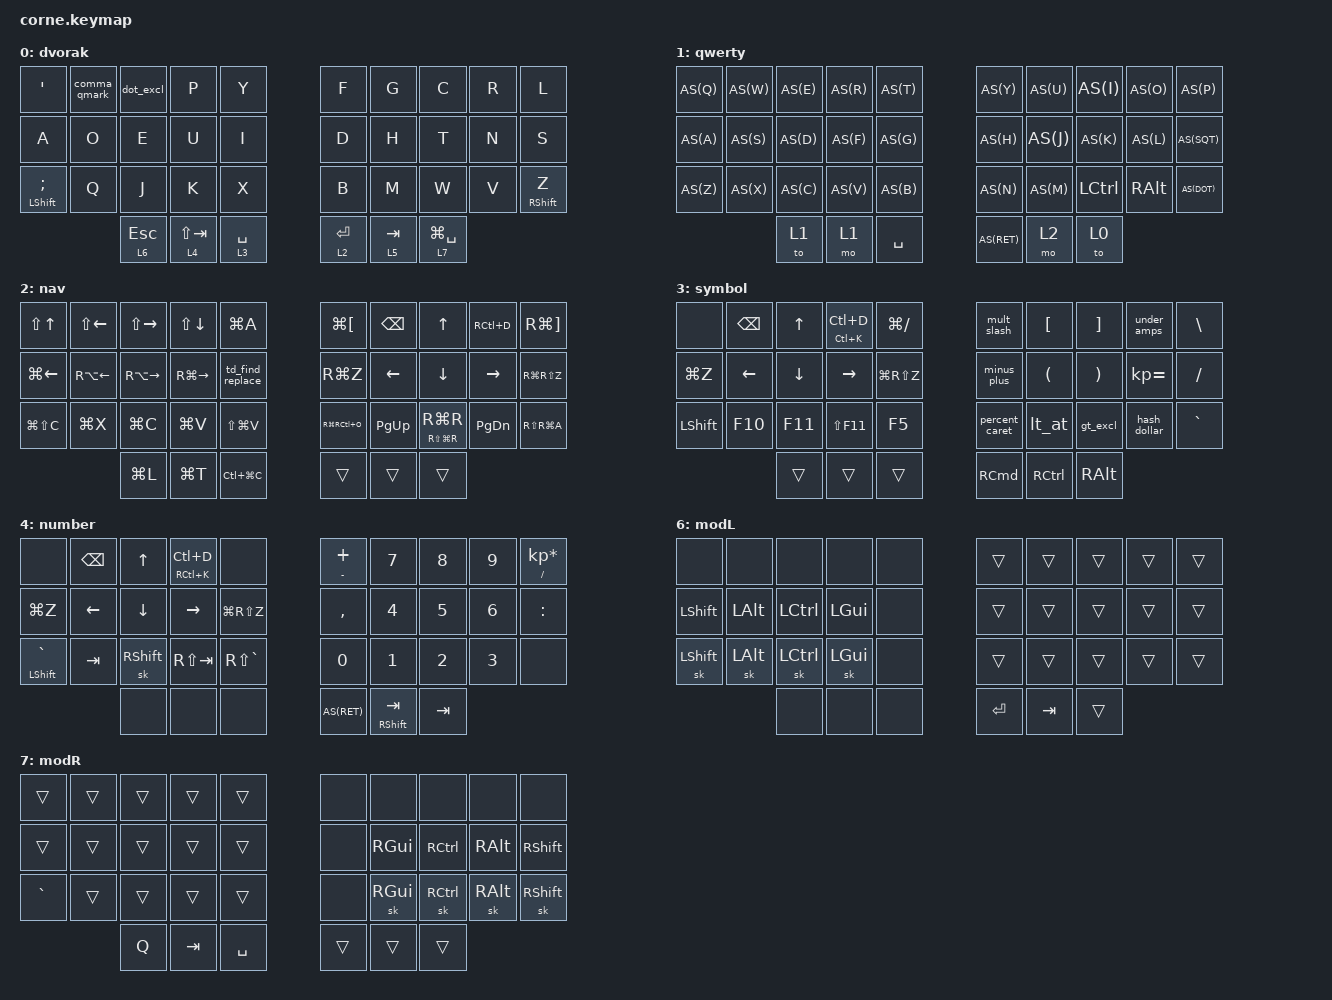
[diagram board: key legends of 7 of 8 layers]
/*
 * Copyright (c) 2020 The ZMK Contributors
 *
 * SPDX-License-Identifier: MIT
 */

#include <behaviors.dtsi>
#include <dt-bindings/zmk/keys.h>
#include <dt-bindings/zmk/bt.h>

#define AS(keycode) &as LS(keycode) keycode

/ {
    chosen {
        zmk,physical-layout = &foostan_corne_5col_layout;
    };

    behaviors {
        as: auto_shift {
            compatible = "zmk,behavior-hold-tap";
            #binding-cells = <2>;
            tapping_term_ms = <200>;
            quick_tap_ms = <0>;
            flavor = "tap-preferred";
            bindings = <&kp>, <&kp>;
        };
        lt_long: lt_long {
            compatible = "zmk,behavior-hold-tap";
            #binding-cells = <2>;
            tapping_term_ms = <350>;
            quick_tap_ms = <0>;
            flavor = "hold-preferred";
            bindings = <&mo>, <&kp>;
        };
        mt_shift: mt_shift {
            compatible = "zmk,behavior-hold-tap";
            #binding-cells = <2>;
            tapping_term_ms = <250>;
            quick_tap_ms = <0>;
            flavor = "hold-preferred";
            bindings = <&kp>, <&kp>;
        };
        td_find_replace: td_find_replace {
            compatible = "zmk,behavior-tap-dance";
            #binding-cells = <0>;
            tapping-term-ms = <200>;
            bindings = <&kp LG(F)>, <&kp LA(LG(F))>;
        };
        cmd_alt: cmd_alt {
            compatible = "zmk,behavior-mod-morph";
            label = "cmd alt";
            #binding-cells = <0>;
            bindings = <&sk LCMD>, <&sk LALT>;
            mods = <(MOD_LSFT|MOD_RSFT)>;
        };

        dot_excl: dot_excl {
            compatible = "zmk,behavior-mod-morph";
            label = "dot exc";
            #binding-cells = <0>;
            bindings = <&kp DOT >, <&kp EXCL >;
            mods = <(MOD_LSFT|MOD_RSFT)>;
        };
        comma_qmark: comma_qmark {
            compatible = "zmk,behavior-mod-morph";
            label = "comma question";
            #binding-cells = <0>;
            bindings = <&kp COMMA>, <&kp QMARK>;
            mods = <(MOD_LSFT|MOD_RSFT)>;
        };

        mult_slash: mult_slash {
            compatible = "zmk,behavior-mod-morph";
            label = "mult slash";
            #binding-cells = <0>;
            bindings = <&kp KP_MULTIPLY>, <&kp KP_SLASH>;
            mods = <(MOD_LSFT|MOD_RSFT)>;
        };
        minus_plus: minus_plus {
            compatible = "zmk,behavior-mod-morph";
            label = "minus plus";
            #binding-cells = <0>;
            bindings = <&kp KP_MINUS>, <&kp KP_PLUS>;
            mods = <(MOD_LSFT|MOD_RSFT)>;
        };

        zoom: zoom {
            compatible = "zmk,behavior-mod-morph";
            label = "minus plus";
            #binding-cells = <0>;
            bindings = <&kp RG(KP_PLUS)>, <&kp RG(KP_MINUS)>;
            mods = <(MOD_LSFT|MOD_RSFT)>;
        };

        percent_caret: percent_caret {
            compatible = "zmk,behavior-mod-morph";
            label = "caret percent";
            #binding-cells = <0>;
            bindings = <&kp PERCENT>, <&kp CARET>;
            mods = <(MOD_LSFT|MOD_RSFT)>;
        };
        lt_at: lt_at {
            compatible = "zmk,behavior-mod-morph";
            label = "lt at";
            #binding-cells = <0>;
            bindings = <&kp LT>, <&kp AT>;
            mods = <(MOD_LSFT|MOD_RSFT)>;
        };
        gt_excl: gt_excl {
            compatible = "zmk,behavior-mod-morph";
            label = "gt excl";
            #binding-cells = <0>;
            bindings = <&kp GT>, <&kp EXCL>;
            mods = <(MOD_LSFT|MOD_RSFT)>;
        };
        hash_dollar: hash_dollar {
            compatible = "zmk,behavior-mod-morph";
            label = "hash dollar";
            #binding-cells = <0>;
            bindings = <&kp HASH>, <&kp DOLLAR>;
            mods = <(MOD_LSFT|MOD_RSFT)>;
        };
        under_amps: under_amps {
            compatible = "zmk,behavior-mod-morph";
            label = "under amps";
            #binding-cells = <0>;
            bindings = <&kp UNDER>, <&kp AMPS>;
            mods = <(MOD_LSFT|MOD_RSFT)>;
        };
    };

    combos {
        compatible = "zmk,combos";
    };

    macros {
        tab_search: tab_search {
            compatible = "zmk,behavior-macro";
            #binding-cells = <0>;
            bindings
                = <&macro_tap &kp LG(L) &kp PERCENT &kp SPACE>
                ;
        };
        bookmark_search: bookmark_search {
            compatible = "zmk,behavior-macro";
            #binding-cells = <0>;
            bindings
                = <&macro_tap &kp LG(L) &kp STAR &kp SPACE>
                ;
        };


    };

        keymap {
            compatible = "zmk,keymap";

            dvorak: dvorak {
                display-name = "dvorak";
                bindings = <
   &kp SQT          &comma_qmark   &dot_excl    &kp P    &kp Y         &kp F    &kp G    &kp C    &kp R   &kp L
   &kp A            &kp O          &kp E        &kp U    &kp I         &kp D    &kp H    &kp T    &kp N   &kp S
   &mt_shift LSHIFT SEMI  &kp Q          &kp J        &kp  K    &kp X        &kp B    &kp M    &kp W    &kp V   &mt_shift RSHIFT Z
              &lt 6 ESC   &lt 4 LS(TAB)  &lt 3 SPACE        &lt 2 RET   &lt 5 TAB  &lt 7 LG(SPACE)
                        >;
                };

            qwerty: qwerty {
                        display-name = "qwerty";
                        bindings = <
   AS(Q) AS(W) AS(E) AS(R) AS(T)     AS(Y)   AS(U)  AS(I)     AS(O)     AS(P)
   AS(A) AS(S) AS(D) AS(F) AS(G)     AS(H)   AS(J)  AS(K)     AS(L)     AS(SQT)
   AS(Z) AS(X) AS(C) AS(V) AS(B)     AS(N)   AS(M)  &kp LCTRL  &kp RALT  AS(DOT)
        &to 1   &mo 1 &kp SPACE     AS(RET) &mo 2  &to 0
                        >;
                };

            nav: nav {
                        display-name = "nav";
                        bindings = <

   &kp LS(UP)           &kp LS(LEFT)     &kp LS(RIGHT)    &kp LS(DOWN)   &kp LG(A)               &kp LG(LBKT)     &kp BACKSPACE    &kp UP                 &kp RC(D)      &kp RG(RBKT)
   &kp LG(LEFT)         &kp RA(LEFT)     &kp RA(RIGHT)    &kp RG(RIGHT)  &td_find_replace         &kp RG(Z)        &kp LEFT         &kp DOWN               &kp RIGHT      &kp RG(RS(Z))
   &kp LG(LS(C))        &kp LG(X)        &kp LG(C)        &kp LG(V)      &kp LS(LG(V))           &kp RG(RC(O))      &kp PG_UP        &mt RS(LG(R)) RG(R)  &kp PG_DN      &kp RS(RG(A))
                                &kp LG(L)    &kp LG(T)    &kp LC(LG(C))                          &trans   &trans    &trans
                        >;
                };

            sym: sym {
                        display-name = "symbol";
                        bindings = <
&none          &kp BACKSPACE   &kp  UP         &mt LC(K) LC(D) &kp LG(SLASH)       &mult_slash      &kp LBKT    &kp RBKT    &under_amps    &kp BACKSLASH
&kp LG(Z)      &kp LEFT        &kp DOWN        &kp RIGHT       &kp LG(RS(Z))       &minus_plus      &kp LPAR    &kp RPAR    &kp KP_EQUAL   &kp SLASH
&kp LSHIFT     &kp F10         &kp F11         &kp LS(F11)     &kp F5              &percent_caret   &lt_at      &gt_excl    &hash_dollar   &kp GRAVE
                                            &trans   &trans    &trans              &kp RCMD     &kp RCTRL     &kp RALT
                        >;
                };

            num: num {
                        display-name = "number";
                        bindings = <
&none             &kp BACKSPACE   &kp  UP         &mt RC(K) LC(D) &none                   &mt MINUS PLUS  &kp N7       &kp N8       &kp N9       &mt SLASH KP_MULTIPLY
&kp LG(Z)         &kp LEFT        &kp DOWN        &kp RIGHT       &kp LG(RS(Z))           &kp COMMA       &kp N4       &kp N5       &kp N6       &kp COLON
&mt LSHIFT GRAVE  &kp TAB         &sk RSHIFT      &kp RS(TAB)     &kp RS(GRAVE)           &kp N0          &kp N1       &kp N2       &kp N3       &none  
                                  &none           &none           &none                   AS(RET)         &mt RSHIFT TAB          &kp TAB
                        >;
                };


            system: system {
                        display-name = "function";
                        bindings = <
   &bt BT_SEL 0      &bt BT_SEL 1  &bt BT_SEL 2  &bt BT_SEL 3  &bt BT_CLR                  &kp RC(RA(UP))             &mt LG(LC(LA(LEFT))) LC(LA(LEFT)) &kp  LC(LA(RET))    &mt LG(LC(LA(RIGHT))) LC(LA(RIGHT))   &kp RC(RA(DOWN))    
   &kp C_MUTE        &kp C_VOL_DN  &kp C_VOL_UP  &kp C_BRI_DN  &kp C_BRI_UP                &mt LG(BACKSLASH) LG(DOT)  &kp  RGUI    &kp RG(RC(RA(S)))    &zoom      &kp RG(RC(RA(D)))
   &kp GRAVE         &kp LG(M)     &kp C_PREV    &kp C_NEXT      &kp C_PP                  &kp RG(RC(S))              &kp  RG(S)   &kp RG(N)      &kp RS(RG(N))    &kp RSHIFT
                                            &kp Q   &kp W  &kp TAB                &trans  &trans  &trans
                        >;
                };

            modL: modL {
                        display-name = "modL";
                        bindings = <
   &none      &none     &none      &none     &none          &trans   &trans   &trans   &trans   &trans    
   &kp LSHIFT &kp LALT  &kp LCTRL  &kp LGUI  &none          &trans   &trans   &trans   &trans   &trans
   &sk LSHIFT &sk LALT  &sk LCTRL  &sk LGUI  &none          &trans   &trans   &trans   &trans   &trans
                        &none      &none     &none          &kp RET  &kp TAB  &trans
                        >;
                };
            modR: modR {
                        display-name = "modR";
                        bindings = <
   &trans        &trans    &trans      &trans     &trans          &none   &none   &none   &none   &none    
   &trans        &trans    &trans      &trans     &trans          &none   &kp RGUI  &kp RCTRL    &kp RALT   &kp RSHIFT
   &kp GRAVE     &trans    &trans      &trans     &trans          &none   &sk RGUI  &sk RCTRL    &sk RALT   &sk RSHIFT
                        &kp Q   &kp TAB   &kp SPACE       &trans  &trans  &trans
                        >;
                };
        };
};
